# LPC844 register map
Vendor: nxp.com; File version: 1.0
CPU: CM0PLUS r0p0, little endian, no MPU, no FPU, VTOR, 2 interrupt priority bits
Registers are 32-bit, read-write, reset 0x0 unless marked. A register's access mark holds for its fields unless they carry their own. Offsets are from the block's base; [hi:lo] are bit positions; {n}, {i} and the like mark numbered series; 'fields as' and 'values as' point back to an identical list.

## WKT — LPC84x Wake Up Timer(WKT)
Base 0x40008000
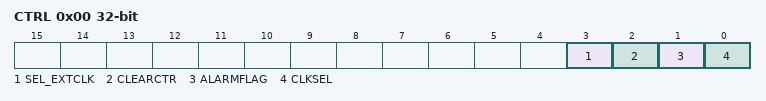
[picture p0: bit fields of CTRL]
0x00 CTRL — Self wake-up timer control register.
  [3] SEL_EXTCLK — Select external or internal clock source for the self wake-up timer. The internal clock source is selected by the CLKSEL bit in this register if SET_EXTCLK is set to internal.
    0=INTERNAL (Internal. The clock source is the internal clock selected by the CLKSEL bit.); 1=EXTERNAL (External. The self wake-up timer uses the external WKTCLKIN pin.)
  [2] CLEARCTR — Clears the self wake-up timer.
    0=NO_EFFECT (No effect. Reading this bit always returns 0.); 1=CLEAR_THE_COUNTER (Clear the counter. Counting is halted until a new count value is loaded.)
  [1] ALARMFLAG — Wake-up or alarm timer flag.
    0=NO_TIME_OUT (No time-out. The self wake-up timer has not timed out. Writing a 0 to has no effect.); 1=TIME_OUT (Time-out. The self wake-up timer has timed out. This flag generates an interrupt request which can wake up the part from any reduced power mode including Deep power-down if the clock source is the low power oscillator. Writing a 1 clears this status bit.)
  [0] CLKSEL — Select the self wake-up timer clock source. Remark: This bit only has an effect if the SEL_EXTCLK bit is not set.
    0=DIVIDED_IRC_CLOCK (Divided IRC clock. This clock runs at 750 kHz and provides time-out periods of up to approximately 95 minutes in 1.33 us increments. Remark: This clock is not available in not available in Deep-sleep, power-down, deep power-down modes. Do not select this option if the timer is to be used to wake up from one of these modes.); 1=LOW_POWER_CLOCK (This is the (nominally) 10 kHz clock and provides time-out periods of up to approximately 119 hours in 100 us increments. The accuracy of this clock is limited to +/- 40 % over temperature and processing. Remark: This clock is available in all power modes. Prior to use, the low-power oscillator must be enabled. The oscillator must also be set to remain active in Deep power-down if needed.)
0x0C COUNT reset not defined — Counter register.
  [31:0] VALUE — A write to this register pre-loads start count value into the timer and starts the count-down sequence. A read reflects the current value of the timer.

## ACOMP — LPC84x analog comparator
Base 0x40024000
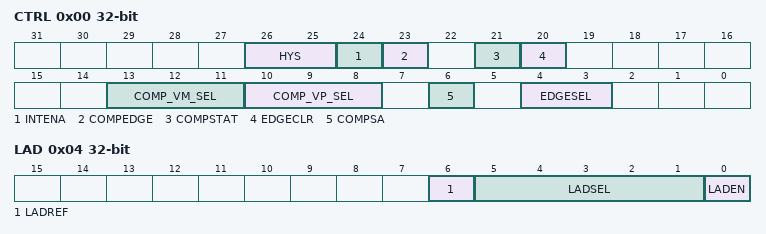
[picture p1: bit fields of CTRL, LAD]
0x00 CTRL (reset mask 0x6C03F58) — Comparator control register
  [26:25] HYS — Controls the hysteresis of the comparator. When the comparator is outputting a certain state, this is the difference between the selected signals, in the opposite direction from the state being output, that will switch the output.
    0=None (the output will switch as the voltages cross); 1=5 mv; 2=10 mv; 3=20 mv
  [24] INTENA — Must be set to generate interrupts.
  [23] COMPEDGE — Comparator edge-detect status.
  [21] COMPSTAT — Comparator status. This bit reflects the state of the comparator output.
  [20] EDGECLR — Interrupt clear bit. To clear the COMPEDGE bit and thus negate the interrupt request, toggle the EDGECLR bit by first writing a 1 and then a 0.
  [13:11] COMP_VM_SEL — Selects negative voltage input
    0=VOLTAGE_LADDER_OUTPUT; {v}=ACMP_I{v} (v=1..5); 6=BAND_GAP (Band gap. Internal reference voltage.); 7=DACOUT0 (DAC0 output)
  [10:8] COMP_VP_SEL — Selects positive voltage input
    values as COMP_VM_SEL
  [6] COMPSA — Comparator output control
    0=Comparator output is used directly; 1=Comparator output is synchronized to the bus clock for output to other modules
  [4:3] EDGESEL — This field controls which edges on the comparator output set the COMPEDGE bit (bit 23 below):
    0=FALLING_EDGES; 1=RISING_EDGES; 2=BOTH_EDGES0; 3=BOTH_EDGES1
0x04 LAD — Voltage ladder register
  [6] LADREF — Selects the reference voltage Vref for the voltage ladder.
    0=Supply pin VDD; 1=VDDCMP pin
  [5:1] LADSEL — Voltage ladder value. The reference voltage Vref depends on the LADREF bit below. 00000 = VSS 00001 = 1 x Vref/31 00010 = 2 x Vref/31 ... 11111 = Vref
  [0] LADEN — Voltage ladder enable

## Notices in the file
Copyright 2016-2019 NXP
All rights reserved.
SPDX-License-Identifier: BSD-3-Clause
